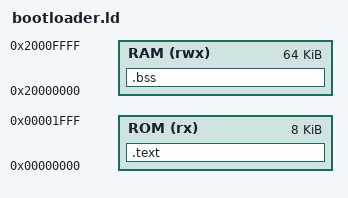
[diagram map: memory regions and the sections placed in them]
ENTRY(_start)

MEMORY
{
  ROM (rx)  : ORIGIN = 0x00000000, LENGTH = 8K
  RAM (rwx) : ORIGIN = 0x20000000, LENGTH = 64K
}

SECTIONS
{
  .text : {
    KEEP(*(.text.start))
    *(.text*)
    *(.rodata*)
  } > ROM

  .bss (NOLOAD) : {
    _sbss = .;
    *(.bss*)
    *(COMMON)
    _ebss = .;
  } > RAM

  _stack_top = ORIGIN(RAM) + LENGTH(RAM);
}
